# rCSL_psc0_001 register map
Vendor: Texas Instruments
Peripheral module from a debugger description file (folder c674x).
Registers are 32-bit, access not given, reset 0x0 unless marked. A register's access mark holds for its fields unless they carry their own. Offsets are as the file gives them; lines under a group give offsets from that group; [hi:lo] are bit positions; {n}, {i} and the like mark numbered series; 'fields as' and 'values as' point back to an identical list; <NAME> marks a mode.

## PSC0 — ASP Power and Sleep Controller (PSC) Version 2.0.1
0x00 REV ro reset 0x44823A00 — Peripheral Revision and Class Information
  [31:0] REV — PSC module Revision ID
0x18 INTEVAL — Interrupt Evaluation Register
  [0] ALLEV wo — Re Evaluate combined PSC interrupt 0: Write of 0 has no effect 1: Write of 1 re evaluates the combined PSC interrupt PSC_ALLINT
    0=NO_EFFECT; 1=RE_EVALUATE
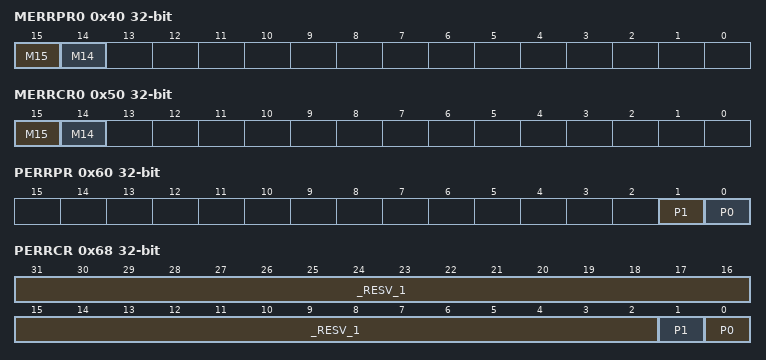
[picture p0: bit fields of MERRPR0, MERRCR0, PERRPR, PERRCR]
0x40 MERRPR0 — Module Error Pending 0 Register
  [15] M15 ro — Records pending error condition for module 15. Each bit n respresents a module. For each bit n, 0: Module n does not have error condition 1: Module n has error condition
    0=NO_ERR; 1=ERROR
  [14] M14 ro — Records pending error condition for module 14. Each bit n respresents a module. For each bit n, 0: Module n does not have error condition 1: Module n has error condition
    0=NO_ERR; 1=ERROR
0x50 MERRCR0 — Module Error Clear 0 Register
  [15] M15 wo — Clears error bit set in corresponding MERRPR register bit field. This pertains module 15 .For each bit n, 0: Write of 0 has no effect 1: Write of 1 to bit n causes ERRPR bit n to be cleared, and the corresponding module's MDSTAT fields to be cleared EMURST/EMUIHB
    0=NO_EFFECT; 1=CLR_ERR
  [14] M14 wo — Clears error bit set in corresponding MERRPR register bit field. This pertains to module 14.For each bit n, 0: Write of 0 has no effect 1: Write of 1 to bit n causes ERRPR bit n to be cleared, and the corresponding module's MDSTAT fields to be cleared EMURST/EMUIHB
    0=NO_EFFECT; 1=CLR_ERR
0x60 PERRPR — Power Error Pending Register
  [1] P1 ro — DSPSS Power Domain (PD1) Error Condition 0: Power domain n does not have error condition 1: Power domain n has error condition
    0=NO_ERR; 1=ERROR
  [0] P0 ro — Always On Power Domain (PD0) Error Condition 0: Power domain n does not have error condition 1: Power domain n has error condition
    0=NO_ERR; 1=ERROR
0x68 PERRCR — Power Error Clear Register
  [31:2] _RESV_1 — (access N)
  [1] P1 — DSPSS Power Domain (PD1) Error Clear Register 0: Write of 0 has no effect 1: Write of 1 clears the corresponding PERRPR bit
    0=NO_EFFECT; 1=CLR_ERR
  [0] P0 wo — Always On Power Domain (PD0) Error Clear Register 0: Write of 0 has no effect 1: Write of 1 clears the corresponding PERRPR bit
    0=NO_EFFECT; 1=CLR_ERR
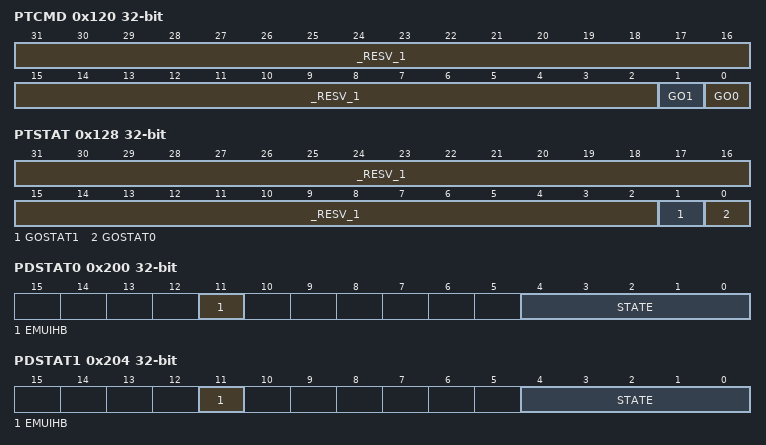
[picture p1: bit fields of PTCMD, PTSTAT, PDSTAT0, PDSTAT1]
0x120 PTCMD — Power Domain Transition Command Register
  [31:2] _RESV_1 — (access N)
  [1] GO1 rw — DSPSS Power Domain (PD1) GO Transition 0: Writes of 0 have no effect 1: Writes of 1 cause PSC hardware to evaluate PDCTL.NEXT and MDCTL.NEXT (for this domain).
    0=NO_EFFECT; 1=SET
  [0] GO0 rw — Always On Power Domain (PD0) GO Transition 0: Writes of 0 have no effect 1: Writes of 1 cause PSC hardware to evaluate PDCTL.NEXT and MDCTL.NEXT (for this domain).
    0=NO_EFFECT; 1=SET
0x128 PTSTAT — Power Domain Transition Status Register
  [31:2] _RESV_1 — (access N)
  [1] GOSTAT1 ro — DSPSS Power Domain (PD1) Transition Command Status 0: No transitions in progress in Power Domain n 1: Power Domain 0 Transition in progress.Either the power domain is transitioning, or modules on this domain are transitioning.
    0=NO_TRANSITION; 1=IN_TRANSITION
  [0] GOSTAT0 ro — Always On Power Domain (PD0) Transition Command Status 0: No transitions in progress in Power Domain n 1: Power Domain 0 Transition in progress.Either the power domain is transitioning, or modules on this domain are transitioning. Note: Power domain 0 is reserved for the Always ON domain, this bit is always 0.
    0=NO_TRANSITION; 1=IN_TRANSITION
0x200 PDSTAT0 — Power Domain Status 0 (Always On) Register
  [11] EMUIHB ro — Emulation Alters Domain State _ Inhibits Off or Forces ON 0: No emulation altering user_desired power domain state 1: Emulation alters user_desired power state
    0=INHIBIT_OFF; 1=INHIBIT_ON
  [4:0] STATE ro — Current Power Domain State 00000: Off 00001: On 00010 - 01111: Reserved 10000 - 11010: In Transition 11011 - 11111: Reserved
    0=OFF; 1=ON
0x204 PDSTAT1 — Power Domain Status 1 (DSPSS Power Domain) Register
  fields as PDSTAT0
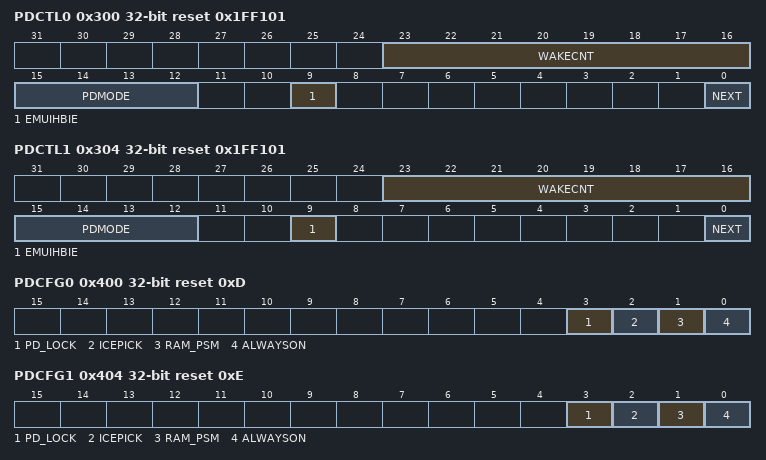
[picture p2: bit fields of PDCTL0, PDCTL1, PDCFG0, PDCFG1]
0x300 PDCTL0 reset 0x1FF101 — Power Domain Control 0 Register
  [23:16] WAKECNT rw — RAM wake count delay value. Not recommended to change the default values 23:20 GOOD2ACCESS wake delay 19:16 ON2GOOD wake delay
  [15:12] PDMODE ro — Power Down Mode 1111: Core On, RAM Array On, RAM Periphery On 0000 - 1110 : Reserved/ Don't Care
  [9] EMUIHBIE rw — Emulation alters domain state (Inhibits domain Off or Forces Domain On) Interrupt Enable 0: Not enabled 1: Enabled
    0=DISABLE; 1=ENABLE
  [0] NEXT rw — User_Desired Next Power Domain State 0: Off 1: On
    0=OFF; 1=ON
0x304 PDCTL1 reset 0x1FF101 — Power Domain Control 1 Register
  [23:16] WAKECNT rw — RAM wake count delay value. Not recommended to change the default values 23:20 GOOD2ACCESS wake delay 19:16 ON2GOOD wake delay
  [15:12] PDMODE rw — Power Down Mode 0000: Core Off , RAM Array Off, Ram Periphery Off 0001: Core Off, RAM Array Retention, RAM Periphery Off (Deep Sleep) 0010: Reserved 0011: Reserved 0100: Core Retention, RAM Array Off, RAM Periphery Off 0101: Core Retention, RAM Array Retention, RAM Periphery Off (Deep Sleep) 0110: Reserved 0111: Reserved 1000: Core On , RAM Array Off, Ram Periphery Off 1001: Core On, RAM Array Retention, RAM Periphery Off (Deep Sleep) 1010: Core On, RAM Array Retention, RAM Periphery Off (Light Sleep) 1011: Core On, RAM Array Retention, RAM Periphery On 1100: Reserved 1101: Reserved 1110: Reserved 1111: Core On, RAM Array On, RAM Periphery On
    0=OFF; 8=RAM_OFF; 9=DEEP_SLEEP; 10=LIGHT_SLEEP; 11=RETENTION; 15=ON
  [9] EMUIHBIE rw — Emulation alters domain state (Inhibits domain Off or Forces Domain On) Interrupt Enable 0: Not enabled 1: Enabled
    0=DISABLE; 1=ENABLE
  [0] NEXT rw — User_Desired Next Power Domain State 0: Off 1: On
    0=OFF; 1=ON
0x400 PDCFG0 reset 0xD — Power domain configaration register
  [3] PD_LOCK ro — PDCTL.NEXT lock 0:PDCTL.Next is locked and cannot be changed in software 1:PDCTL.Next is not locked. For Always On Domain this is a don't care
    0=YES; 1=NO
  [2] ICEPICK ro — Icepick Support 0: Not Present 1: Present
    0=ABSENT; 1=PRESENT
  [1] RAM_PSM ro — RAM Power Domain 0: Not a Ram Power Domain 1: Ram Power Domain
    0=NO; 1=YES
  [0] ALWAYSON ro — Always On Power Domain 0: Not an Always On Domain 1: Always On Domain
    0=NO; 1=YES
0x404 PDCFG1 reset 0xE — Power domain configaration register
  fields as PDCFG0
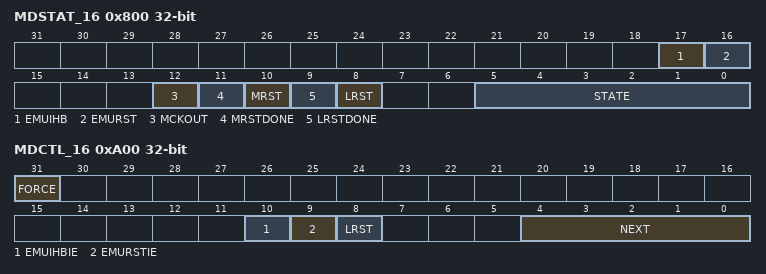
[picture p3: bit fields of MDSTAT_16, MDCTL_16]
0x800 MDSTAT_16 — Module Status 0 Register
  [17] EMUIHB ro — Emulation Alters Module State . Inhibits Module Inactive or Force Module Active 0: No emulation altering user desired module state
    0=DISABLE; 1=ENABLE
  [16] EMURST ro — Emulation Alters Reset (local or module reset ) to Module 0: No emulation altering user_desired reset 1: Emulation alters user_desired module state
    0=DISABLE; 1=ENABLE
  [12] MCKOUT ro — Actual modclk output to module
    0=OFF; 1=ON
  [11] MRSTDONE ro — Module reset intialization done status 0: Module reset initialization not done 1: Module reset initialization done
    0=COMPLETE; 1=INCOMPLETE
  [10] MRST ro — Module reset actual status 0: Modlule reset asserted 1: Module reset de-asserted
    0=ASSERT; 1=DEASSERT
  [9] LRSTDONE ro — Module local reset intialization done stauts 0: local reset initialization not done 1: local reset initialization done
    0=NOTDONE; 1=DONE
  [8] LRST ro — Module local reset actual status 0: local reset asserted 1: local reset de_asserted
    0=ASSERT; 1=DEASSERT
  [5:0] STATE ro — Module Next State 000000: SwRstDisable 000001: SyncReset 000010: Disable 000011: Enable 000100: AutoSleep 000101: Auto Wake Others: Reserved/Invalid State If the module is AUTO ONLY, SwRstDisable, SynReset and Disable states are note allowed, will cause the module to transition to Enable
    0=SWRSTDISABLE; 1=SYNCRST; 2=DISABLE; 3=ENABLE; 4=AUTOSLEEP; 5=AUTOWAKE
0xA00 MDCTL_16 — Module Control 0 Register
  [31] FORCE rw — Force bit 0: no force 1: force
    0=DISABLE; 1=ENABLE
  [10] EMUIHBIE rw — Emulation alters module state _ Inhibits Module Inactive or Force Module Active 0: Not enabled
    0=DISABLE; 1=ENABLE
  [9] EMURSTIE rw — Emulation Alter Reset Interrupt Enable 0: Not enabled 1: Interrupt Enabled
    0=DISABLE; 1=ENABLE
  [8] LRST rw — Module local reset control for ARM 0: Assert local reset 1: De_assert local reset
    0=ASSERT; 1=DEASSERT
  [4:0] NEXT rw — Module Next State 000000: SwRstDisable 000001: SyncReset 000010: Disable 000011: Enable 000100: AutoSleep 000101: Auto Wake Others: Reserved/Invalid State If the module is AUTO ONLY, SwRstDisable, SynReset and Disable states are note allowed, will cause the module to transition to Enable
    values as MDSTAT_16.STATE
